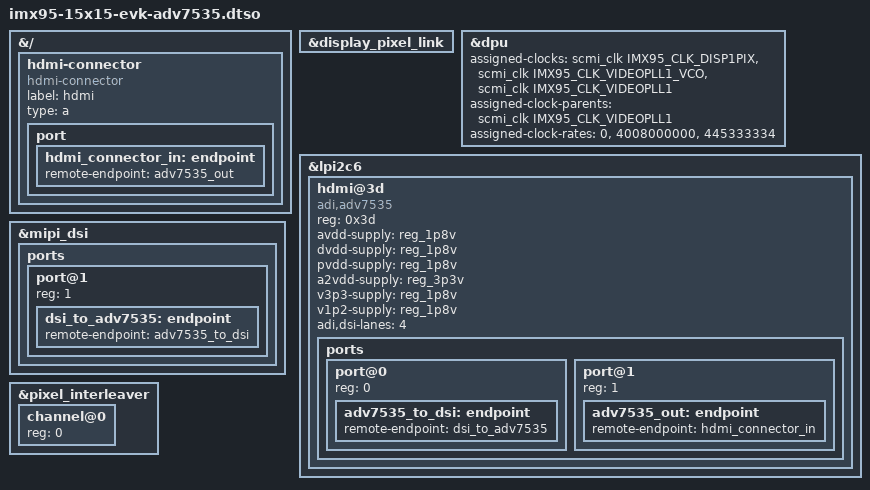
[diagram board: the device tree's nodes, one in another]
// SPDX-License-Identifier: (GPL-2.0+ OR MIT)
/*
 * Copyright 2024 NXP
 */

/dts-v1/;
/plugin/;

#include <dt-bindings/clock/fsl,imx95-clock.h>

&{/} {
	hdmi-connector {
		compatible = "hdmi-connector";
		label = "hdmi";
		type = "a";

		port {
			hdmi_connector_in: endpoint {
				remote-endpoint = <&adv7535_out>;
			};
		};
	};
};

&display_pixel_link {
	status = "okay";
};

&dpu {
	assigned-clocks = <&scmi_clk IMX95_CLK_DISP1PIX>,
			  <&scmi_clk IMX95_CLK_VIDEOPLL1_VCO>,
			  <&scmi_clk IMX95_CLK_VIDEOPLL1>;
	assigned-clock-parents = <&scmi_clk IMX95_CLK_VIDEOPLL1>;
	assigned-clock-rates = <0>, <4008000000>, <445333334>;
};

&lpi2c6 {
	#address-cells = <1>;
	#size-cells = <0>;

	hdmi@3d {
		compatible = "adi,adv7535";
		reg = <0x3d>;
		avdd-supply = <&reg_1p8v>;
		dvdd-supply = <&reg_1p8v>;
		pvdd-supply = <&reg_1p8v>;
		a2vdd-supply = <&reg_3p3v>;
		v3p3-supply = <&reg_1p8v>;
		v1p2-supply = <&reg_1p8v>;
		adi,dsi-lanes = <4>;

		ports {
			#address-cells = <1>;
			#size-cells = <0>;

			port@0 {
				reg = <0>;

				adv7535_to_dsi: endpoint {
					remote-endpoint = <&dsi_to_adv7535>;
				};
			};

			port@1 {
				reg = <1>;

				adv7535_out: endpoint {
					remote-endpoint = <&hdmi_connector_in>;
				};
			};
		};
	};
};

&mipi_dsi {
	status = "okay";

	ports {
		#address-cells = <1>;
		#size-cells = <0>;

		port@1 {
			reg = <1>;

			dsi_to_adv7535: endpoint {
				remote-endpoint = <&adv7535_to_dsi>;
			};
		};
	};
};

&pixel_interleaver {
	#address-cells = <1>;
	#size-cells = <0>;
	status = "okay";

	channel@0 {
		reg = <0>;
		status = "okay";
	};
};
